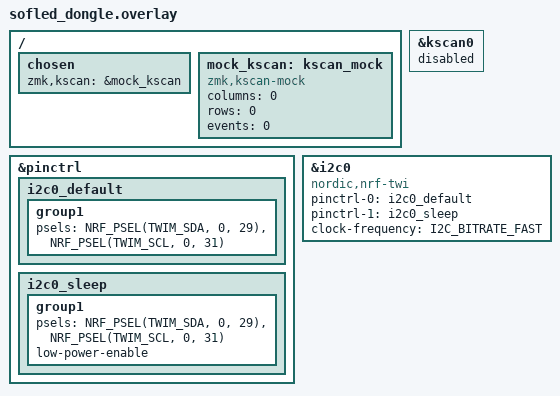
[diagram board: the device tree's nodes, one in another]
/*
 * Copyright (c) 2020 Ryan Cross
 *
 * SPDX-License-Identifier: MIT
 */

#include "sofled.dtsi"

/* The dongle has no switches. The shared sofled.dtsi matrix would drive
 * pro_micro 19 (P0.29) — which is also I2C SDA below — and fight the OLED
 * bus. Use a mock kscan instead and disable the matrix. */
/ {
    chosen {
        zmk,kscan = &mock_kscan;
    };

    mock_kscan: kscan_mock {
        compatible = "zmk,kscan-mock";
        columns = <0>;
        rows = <0>;
        events = <0>;
    };
};

&kscan0 {
    status = "disabled";
};

&pinctrl {
    i2c0_default: i2c0_default {
        group1 {
            psels = <NRF_PSEL(TWIM_SDA, 0, 29)>,
                    <NRF_PSEL(TWIM_SCL, 0, 31)>;
        };
    };

    i2c0_sleep: i2c0_sleep {
        group1 {
            psels = <NRF_PSEL(TWIM_SDA, 0, 29)>,
                    <NRF_PSEL(TWIM_SCL, 0, 31)>;
                    low-power-enable;
        };
    };
};

&i2c0 {
    compatible = "nordic,nrf-twi";
    pinctrl-0 = <&i2c0_default>;
    pinctrl-1 = <&i2c0_sleep>;
    pinctrl-names = "default", "sleep";
    /* 400 kHz: default 100 kHz makes a full SSD1306 frame ~45 ms. */
    clock-frequency = <I2C_BITRATE_FAST>;
};
